# TC80_VXX register map
Vendor: Geneal MCU Ltd.; Series: ARMCM0; File version: 1.2
CPU: CM0 r0p0, little endian, no MPU, no FPU, 2 interrupt priority bits
Registers are 32-bit, read-write, reset 0x0 unless marked. A register's access mark holds for its fields unless they carry their own. Offsets are from the block's base; [hi:lo] are bit positions.

## I2C0 — Inter-integrated circuit
Base 0x49005000
0x00 TDR — Transmit data register
  [7:0] DATA — Transmit data
0x04 RDR ro — Receive data register
  [7:0] DATA — Transmit data
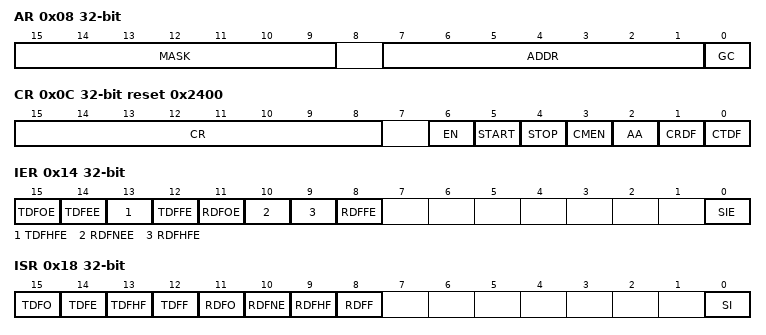
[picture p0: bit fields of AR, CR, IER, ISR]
0x08 AR (reset mask 0xFF) — Address register
  [15:9] MASK — I2C slave address MASK
  [7:1] ADDR — I2C slave address
  [0] GC — General Call
    0=Disable (General call disabled); 1=Enable (General call enabled)
0x0C CR reset 0x2400 (reset mask 0xFF7C) — Control register
  [15:8] CR — Clock rate, Fi2c=Fsys/(CR+1)/4
  [6] EN — I2C enable
    0=Disable (I2C disabled); 1=Enable (I2C enabled)
  [5] START — I2C interface create start signal
    0=No_Action; 1=START (Send start signal)
  [4] STOP — I2C interface create stop signal
    0=No_Action; 1=STOP (Send stop signal)
  [3] CMEN — Continuous mode enable
    0=Disable (Continuous mode disabled); 1=Enable (Continuous mode enabled)
  [2] AA — I2C interface create ackownlege signal
    0=NACK (Return no ack); 1=ACK (Return ack)
  [1] CRDF — Clean receive data fifo
    0=No_Action; 1=Clean receive data fifo
  [0] CTDF — Clean transmit data fifo
    0=No_Action; 1=Clean transmit data fifo
0x10 SR ro — I2C status register
  [7:3] STA — I2C status code
0x14 IER — Interrupt enable register
  [15] TDFOE — Transmit data fifo overflow interrupt enable
    0=Disable (Transmit data fifo overflow interrupt disabled); 1=Enable (Transmit data fifo overflow interrupt enabled)
  [14] TDFEE — Transmit data fifo empty interrupt enable
    0=Disable (Transmit data fifo empty interrupt disabled); 1=Enable (Transmit data fifo empty interrupt enabled)
  [13] TDFHFE — Transmit data fifo half full interrupt enable
    0=Disable (Transmit data fifo half full interrupt disabled); 1=Enable (Transmit data fifo half full interrupt enabled)
  [12] TDFFE — Transmit data fifo full interrupt enable
    0=Disable (Transmit data fifo full interrupt disabled); 1=Enable (Transmit data fifo full interrupt enabled)
  [11] RDFOE — Receive data fifo overflow interrupt enable
    0=Disable (Receive data fifo overflow interrupt disabled); 1=Enable (Receive data fifo overflow interrupt enabled)
  [10] RDFNEE — Receive data fifo not empty interrupt enable
    0=Disable (Receive data fifo not empty interrupt disabled); 1=Enable (Receive data fifo not empty interrupt enabled)
  [9] RDFHFE — Receive data fifo half full interrupt enable
    0=Disable (Receive data fifo half full interrupt disabled); 1=Enable (Receive data fifo half full interrupt enabled)
  [8] RDFFE — Receive data fifo full interrupt enable
    0=Disable (Receive data fifo full interrupt disabled); 1=Enable (Receive data fifo full interrupt enabled)
  [0] SIE — Status change interrupt enable
    0=Disable (Status change interrupt disabled); 1=Enable (Status change interrupt enabled)
0x18 ISR — Interrupt status register
  [15] TDFO — Transmit data fifo overflow interrupt enable
    0=No_TDFO (Transmit data fifo overflow interrupt has no occured); 1=TDFO_Occured (Transmit data fifo overflow interrupt has occured)
  [14] TDFE — Transmit data fifo empty interrupt enable
    0=No_TDFE (Transmit data fifo empty interrupt has no occured); 1=TDFE_Occured (Transmit data fifo empty interrupt has occured)
  [13] TDFHF — Transmit data fifo half full interrupt enable
    0=No_TDFHF (Transmit data fifo half full interrupt has no occured); 1=TDFHF_Occured (Transmit data fifo half full interrupt has occured)
  [12] TDFF — Transmit data fifo full interrupt enable
    0=No_TDFF (Transmit data fifo full interrupt has no occured); 1=TDFF_Occured (Transmit data fifo full interrupt has occured)
  [11] RDFO — Receive data fifo overflow interrupt enable
    0=No_RDFO (Receive data fifo overflow interrupt has no occured); 1=RDFO_Occured (Receive data fifo overflow interrupt has occured)
  [10] RDFNE — Receive data fifo not empty interrupt enable
    0=No_RDFNE (Receive data fifo not empty interrupt has no occured); 1=RDFNE_Occured (Receive data fifo not empty interrupt has occured)
  [9] RDFHF — Receive data fifo half full interrupt enable
    0=No_RDFHF (Receive data fifo half full interrupt has no occured); 1=RDFHF_Occured (Receive data fifo half full interrupt has occured)
  [8] RDFF — Receive data fifo full interrupt flag
    0=No_RDFF (Receive data fifo full interrupt has no occured); 1=RDFF_Occured (Receive data fifo full interrupt has occured)
  [0] SI — Status change interrupt flag
    0=No_SI (Status change interrupt flag); 1=SI_Occured (Status change interrupt has occured)

## I2C1 — Inter-integrated circuit
Base 0x49005400
Registers as I2C0; these are added or differ:
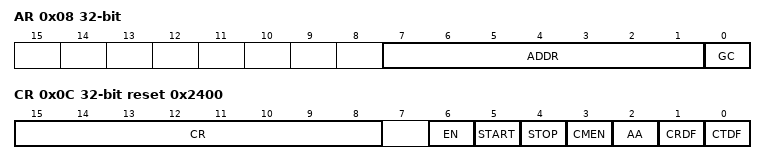
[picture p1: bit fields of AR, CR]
0x08 AR — Address register
  [7:1] ADDR — I2C slave address
  [0] GC — General Call
    0=Disable (General call disabled); 1=Enable (General call enabled)
0x0C CR reset 0x2400 (reset mask 0xFF7C) — Control register
  [15:8] CR — Clock rate, Fi2c=Fsys/(CR+1)/4
  [6] EN — I2C enable
    0=Disable (I2C disabled); 1=Enable (I2C enabled)
  [5] START — I2C interface create start signal
    0=No_Action; 1=START (Send start signal)
  [4] STOP — I2C interface create stop signal
    0=No_Action; 1=STOP (Send stop signal)
  [3] CMEN — Continuous mode enable
    0=Disable (Continuous mode disabled); 1=Enable (Continuous mode enabled)
  [2] AA — I2C interface create ackownlege signal
    0=NACK (Return no ack); 1=ACK (Return ack)
  [1] CRDF — Clean receive data fifo
    0=No_Action; 1=Clean transmit data fifo
  [0] CTDF — Clean transmit data fifo
    0=No_Action; 1=Clean transmit data fifo
0x1C SMR — Slave address mask register
  [6:0] MASK — I2C slave address mask bits
